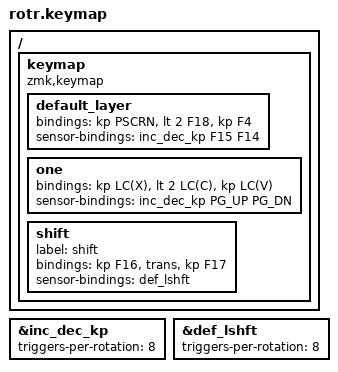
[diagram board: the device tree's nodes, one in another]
#include <behaviors.dtsi>
#include <dt-bindings/zmk/keys.h>
#include <dt-bindings/zmk/rgb.h>
#include <dt-bindings/zmk/bt.h>

&inc_dec_kp {
	triggers-per-rotation = <8>;
};
&def_lshft {
	triggers-per-rotation = <8>;
};

/ {
	keymap {
		compatible = "zmk,keymap";

		default_layer {
			//PSCRN | PLAY/PAUSE | F4
			bindings = <&kp PSCRN &lt 2 F18 &kp F4>;
			sensor-bindings = <&inc_dec_kp F15 F14>;
	
		};
		one {
			//CUT | COPY | PASTE
			bindings = <&kp LC(X) &lt 2 LC(C) &kp LC(V)>;
			sensor-bindings = <&inc_dec_kp PG_UP PG_DN>;
	
		};
		shift {  label = "shift";
			//PREV | PLAY/PAUSE | NEXT
			bindings = <&kp F16 &trans &kp F17>;
			sensor-bindings = <&def_lshft>;
		};
	};
};
